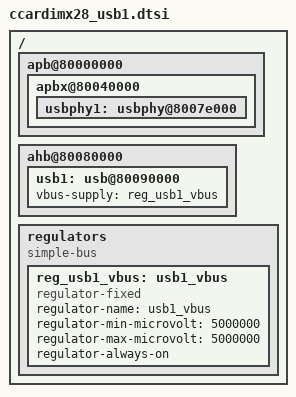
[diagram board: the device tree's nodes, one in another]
/*
 * Copyright 2013 Digi International, Inc.
 *
 * The code contained herein is licensed under the GNU General Public
 * License. You may obtain a copy of the GNU General Public License
 * Version 2 or later at the following locations:
 *
 * http://www.opensource.org/licenses/gpl-license.html
 * http://www.gnu.org/copyleft/gpl.html
 */

/ {
	apb@80000000 {
		apbx@80040000 {
			usbphy1: usbphy@8007e000 {
				status = "okay";
			};
		};
	};

	ahb@80080000 {
		usb1: usb@80090000 {
			vbus-supply = <&reg_usb1_vbus>;
			status = "okay";
		};
	};

	regulators {
		compatible = "simple-bus";

		reg_usb1_vbus: usb1_vbus {
			compatible = "regulator-fixed";
			regulator-name = "usb1_vbus";
			regulator-min-microvolt = <5000000>;
			regulator-max-microvolt = <5000000>;
			regulator-always-on;
		};
	};
};
